VERSION ""

NS_ :

BS_:

BU_: HCU BMS MCU

BO_ 534 MCU_STATUS_4: 8 MCU
 SG_ LiveCounter4 : 63|4@0+ (1,0) [0|0] "" Vector__XXX
 SG_ MotorRotationCount : 55|8@0+ (1,0) [0|0] "" Vector__XXX
 SG_ DCVoltage : 39|16@0+ (1,0) [0|65535] "" Vector__XXX
 SG_ IPMError : 8|1@0+ (1,0) [0|0] "" Vector__XXX
 SG_ UnderVoltageError : 9|1@0+ (1,0) [0|0] "" Vector__XXX
 SG_ Under12vVoltageError : 10|1@0+ (1,0) [0|0] "" Vector__XXX
 SG_ InverterOverTemperatureWarning : 11|1@0+ (1,0) [0|0] "" Vector__XXX
 SG_ WindingOverTemperatureWarning : 12|1@0+ (1,0) [0|0] "" Vector__XXX
 SG_ UnderVoltageWarning : 13|1@0+ (1,0) [0|0] "" Vector__XXX
 SG_ DC_Current : 23|16@0+ (1,-1000) [-1000|1000] "A" Vector__XXX
 SG_ OverVoltageWarning : 14|1@0+ (1,0) [0|0] "" Vector__XXX
 SG_ CANCommunicationError : 7|1@0+ (1,0) [0|0] "" Vector__XXX
 SG_ WindingTemperatureSensorError : 6|1@0+ (1,0) [0|0] "" Vector__XXX
 SG_ ResolverError : 5|1@0+ (1,0) [0|0] "" Vector__XXX
 SG_ InverterOverTemperatureError : 4|1@0+ (1,0) [0|0] "" Vector__XXX
 SG_ WindingOverTemperatureError : 3|1@0+ (1,0) [0|0] "" Vector__XXX
 SG_ OverSpeedError : 2|1@0+ (1,0) [0|0] "" Vector__XXX
 SG_ OverCurrentError : 1|1@0+ (1,0) [0|0] "" Vector__XXX
 SG_ OverVoltageError : 0|1@0+ (1,0) [0|0] "" Vector__XXX

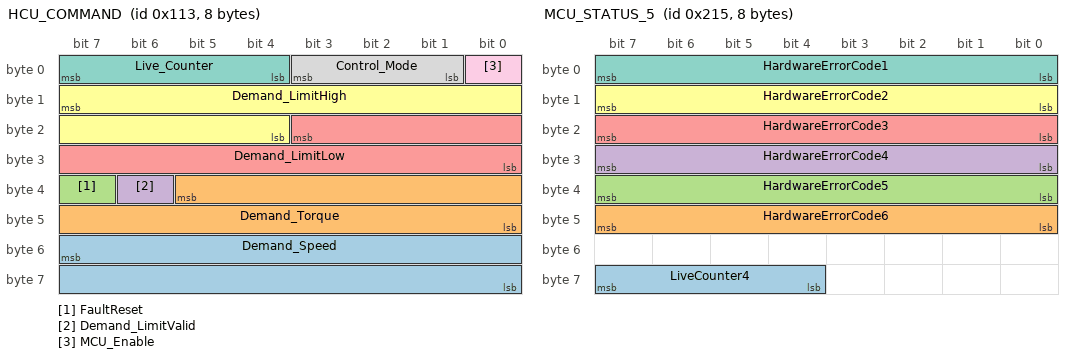
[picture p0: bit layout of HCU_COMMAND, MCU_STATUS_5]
BO_ 275 HCU_COMMAND: 8 HCU
 SG_ Demand_Speed : 55|16@0+ (1,-15000) [0|0] "" Vector__XXX
 SG_ Demand_Torque : 37|14@0+ (1,-5000) [0|0] "" Vector__XXX
 SG_ FaultReset : 39|1@0+ (1,0) [0|0] "" Vector__XXX
 SG_ Demand_LimitValid : 38|1@0+ (1,0) [0|0] "" Vector__XXX
 SG_ Demand_LimitLow : 19|12@0+ (4,0) [0|0] "" Vector__XXX
 SG_ Demand_LimitHigh : 15|12@0+ (4,0) [0|0] "" Vector__XXX
 SG_ Live_Counter : 7|4@0+ (1,0) [0|0] "" Vector__XXX
 SG_ Control_Mode : 3|3@0+ (1,0) [0|0] "" Vector__XXX
 SG_ MCU_Enable : 0|1@0+ (1,0) [0|0] "" Vector__XXX

BO_ 533 MCU_STATUS_5: 8 MCU
 SG_ LiveCounter4 : 63|4@0+ (1,0) [0|15] "" Vector__XXX
 SG_ HardwareErrorCode6 : 47|8@0+ (1,0) [0|0] "" Vector__XXX
 SG_ HardwareErrorCode5 : 39|8@0+ (1,0) [0|0] "" Vector__XXX
 SG_ HardwareErrorCode4 : 31|8@0+ (1,0) [0|0] "" Vector__XXX
 SG_ HardwareErrorCode3 : 23|8@0+ (1,0) [0|0] "" Vector__XXX
 SG_ HardwareErrorCode2 : 15|8@0+ (1,0) [0|0] "" Vector__XXX
 SG_ HardwareErrorCode1 : 7|8@0+ (1,0) [0|0] "" Vector__XXX

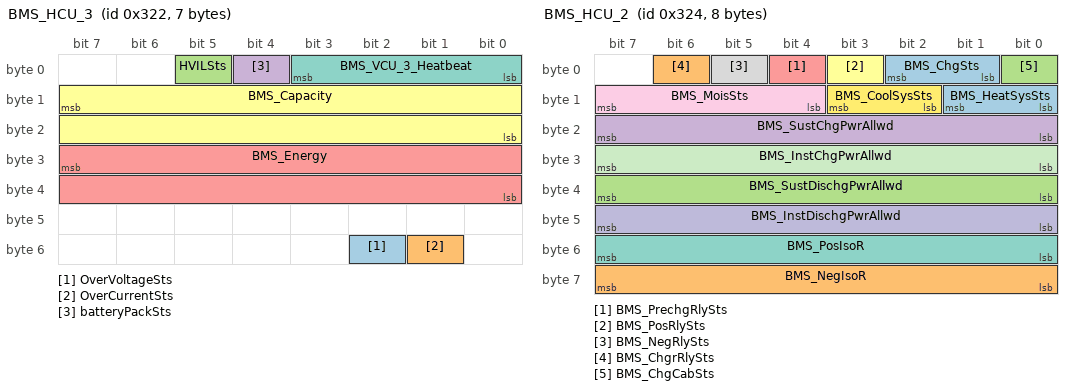
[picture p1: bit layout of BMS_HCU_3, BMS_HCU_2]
BO_ 802 BMS_HCU_3: 7 BMS
 SG_ OverVoltageSts : 50|1@0+ (1,0) [0|0] "" Vector__XXX
 SG_ OverCurrentSts : 49|1@0+ (1,0) [0|0] "" Vector__XXX
 SG_ HVILSts : 5|1@0+ (1,0) [0|0] "" Vector__XXX
 SG_ batteryPackSts : 4|1@0+ (1,0) [0|0] "" Vector__XXX
 SG_ BMS_Energy : 31|16@0+ (0.01,0) [0|200] "" Vector__XXX
 SG_ BMS_Capacity : 15|16@0+ (0.01,0) [0|655.35] "" Vector__XXX
 SG_ BMS_VCU_3_Heatbeat : 3|4@0+ (1,0) [0|15] "" Vector__XXX

BO_ 804 BMS_HCU_2: 8 BMS
 SG_ BMS_HeatSysSts : 9|2@0+ (1,0) [0|0] "" Vector__XXX
 SG_ BMS_NegIsoR : 63|8@0+ (10,0) [0|2550] "k¦¸" Vector__XXX
 SG_ BMS_SustDischgPwrAllwd : 39|8@0+ (1,0) [0|200] "kW" Vector__XXX
 SG_ BMS_SustChgPwrAllwd : 23|8@0+ (1,-200) [-200|0] "kW" Vector__XXX
 SG_ BMS_PrechgRlySts : 4|1@0+ (1,0) [0|3] "" Vector__XXX
 SG_ BMS_PosRlySts : 3|1@0+ (1,0) [0|3] "" Vector__XXX
 SG_ BMS_PosIsoR : 55|8@0+ (10,0) [0|2550] "k¦¸" Vector__XXX
 SG_ BMS_NegRlySts : 5|1@0+ (1,0) [0|3] "" Vector__XXX
 SG_ BMS_MoisSts : 15|4@0+ (10,0) [0|15] "%" Vector__XXX
 SG_ BMS_InstDischgPwrAllwd : 47|8@0+ (1,0) [0|200] "kW" Vector__XXX
 SG_ BMS_InstChgPwrAllwd : 31|8@0+ (1,-200) [-200|0] "kW" Vector__XXX
 SG_ BMS_CoolSysSts : 11|2@0+ (1,0) [0|1] "" Vector__XXX
 SG_ BMS_ChgSts : 2|2@0+ (1,0) [0|3] "" Vector__XXX
 SG_ BMS_ChgrRlySts : 6|1@0+ (1,0) [0|1] "" Vector__XXX
 SG_ BMS_ChgCabSts : 0|1@0+ (1,0) [0|1] "" Vector__XXX

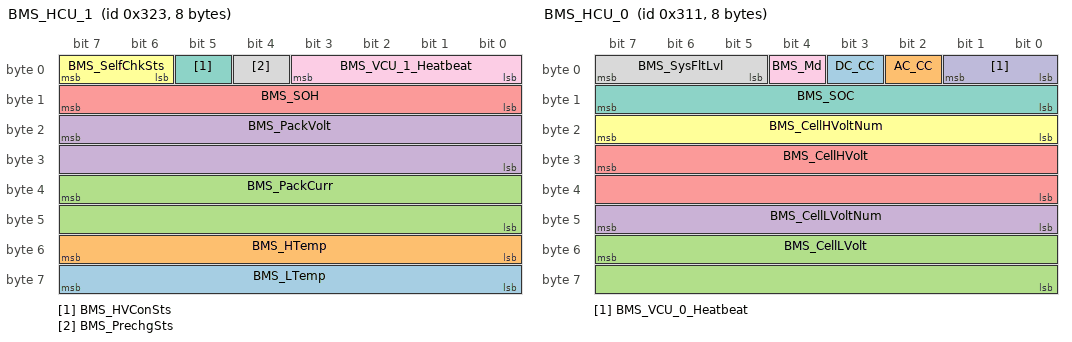
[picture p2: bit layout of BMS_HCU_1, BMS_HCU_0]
BO_ 803 BMS_HCU_1: 8 BMS
 SG_ BMS_LTemp : 63|8@0+ (1,-40) [-40|200] "¡æ" Vector__XXX
 SG_ BMS_HTemp : 55|8@0+ (1,-40) [-40|200] "¡æ" Vector__XXX
 SG_ BMS_PackCurr : 39|16@0+ (1,-1000) [-1000|1000] "A" Vector__XXX
 SG_ BMS_PackVolt : 23|16@0+ (1,0) [0|800] "V" Vector__XXX
 SG_ BMS_SOH : 15|8@0+ (1,0) [0|100] "%" Vector__XXX
 SG_ BMS_SelfChkSts : 7|2@0+ (1,0) [0|3] "" Vector__XXX
 SG_ BMS_HVConSts : 5|1@0+ (1,0) [0|1] "" Vector__XXX
 SG_ BMS_PrechgSts : 4|1@0+ (1,0) [0|1] "" Vector__XXX
 SG_ BMS_VCU_1_Heatbeat : 3|4@0+ (1,0) [0|15] "" Vector__XXX

BO_ 785 BMS_HCU_0: 8 BMS
 SG_ DC_CC : 3|1@0+ (1,0) [0|0] "" Vector__XXX
 SG_ AC_CC : 2|1@0+ (1,0) [0|0] "" Vector__XXX
 SG_ BMS_CellLVolt : 55|16@0+ (0.00390625,0) [0|255.99609375] "V" Vector__XXX
 SG_ BMS_CellLVoltNum : 47|8@0+ (1,0) [0|255] "" Vector__XXX
 SG_ BMS_CellHVolt : 31|16@0+ (0.00390625,0) [0|0] "V" Vector__XXX
 SG_ BMS_CellHVoltNum : 23|8@0+ (1,0) [0|255] "" Vector__XXX
 SG_ BMS_SOC : 15|8@0+ (0.5,0) [0|100] "%" Vector__XXX
 SG_ BMS_SysFltLvl : 7|3@0+ (1,0) [0|4] "" Vector__XXX
 SG_ BMS_Md : 4|1@0+ (1,0) [0|1] "" Vector__XXX
 SG_ BMS_VCU_0_Heatbeat : 1|2@0+ (1,0) [0|3] "" Vector__XXX

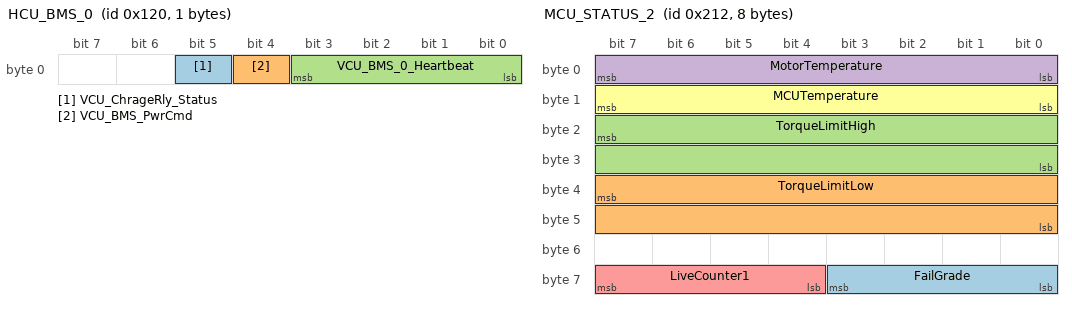
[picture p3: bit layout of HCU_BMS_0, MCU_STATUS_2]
BO_ 288 HCU_BMS_0: 1 HCU
 SG_ VCU_ChrageRly_Status : 5|1@0+ (1,0) [0|0] ""  BMS
 SG_ VCU_BMS_PwrCmd : 4|1@0+ (1,0) [0|1] ""  BMS
 SG_ VCU_BMS_0_Heartbeat : 3|4@0+ (1,0) [0|15] ""  BMS

BO_ 530 MCU_STATUS_2: 8 MCU
 SG_ FailGrade : 59|4@0+ (1,0) [0|0] "" Vector__XXX
 SG_ TorqueLimitLow : 39|16@0+ (1,-5000) [-5000|0] "" Vector__XXX
 SG_ TorqueLimitHigh : 23|16@0+ (1,0) [0|5000] "Nm" Vector__XXX
 SG_ MotorTemperature : 7|8@0+ (1,-40) [-40|215] "¡æ" Vector__XXX
 SG_ LiveCounter1 : 63|4@0+ (1,0) [0|15] "" Vector__XXX
 SG_ MCUTemperature : 15|8@0+ (1,-40) [-40|215] "¡æ" Vector__XXX

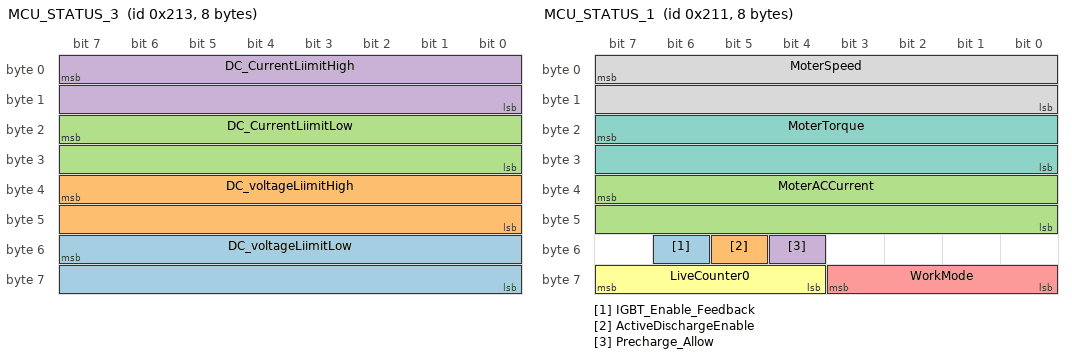
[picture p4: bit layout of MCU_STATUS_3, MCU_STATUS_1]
BO_ 531 MCU_STATUS_3: 8 MCU
 SG_ DC_voltageLiimitLow : 55|16@0+ (0.1,-750) [0|0] "" Vector__XXX
 SG_ DC_voltageLiimitHigh : 39|16@0+ (0.1,0) [0|0] "" Vector__XXX
 SG_ DC_CurrentLiimitLow : 23|16@0+ (0.1,-400) [0|0] "" Vector__XXX
 SG_ DC_CurrentLiimitHigh : 7|16@0+ (0.1,0) [0|0] "" Vector__XXX

BO_ 529 MCU_STATUS_1: 8 MCU
 SG_ IGBT_Enable_Feedback : 54|1@0+ (1,0) [0|0] "" Vector__XXX
 SG_ ActiveDischargeEnable : 53|1@0+ (1,0) [0|0] "" Vector__XXX
 SG_ MoterACCurrent : 39|16@0+ (0.1,0) [0|1000] "" Vector__XXX
 SG_ Precharge_Allow : 52|1@0+ (1,0) [0|1] "" Vector__XXX
 SG_ WorkMode : 59|4@0+ (1,0) [0|8] "" Vector__XXX
 SG_ LiveCounter0 : 63|4@0+ (1,0) [0|15] "" Vector__XXX
 SG_ MoterTorque : 23|16@0+ (1,-5000) [-5000|5000] "Nm" Vector__XXX
 SG_ MoterSpeed : 7|16@0+ (1,-15000) [-15000|15000] "rpm" Vector__XXX

BA_DEF_ SG_  "GenSigSendType" ENUM  "Cyclic","OnWrite","OnWriteWithRepetition","OnChange","OnChangeWithRepetition","IfActive","IfActiveWithRepetition";
BA_DEF_ SG_  "GenSigEnvVarType" ENUM  "int","float","undef";
BA_DEF_ BO_  "GenMsgILSupport" ENUM  "No","Yes";
BA_DEF_ BO_  "GenMsgCycleTimeFast" INT 2 100000;
BA_DEF_ BO_  "GenMsgSendType" ENUM  "Cyclic","not_used","not_used","not_used","not_used","Cyclic","not_used","IfActive";
BA_DEF_ BO_  "GenMsgCycleTime" INT 2 50000;
BA_DEF_ BO_  "GenMsgDelayTime" INT 1 1000;
BA_DEF_ BU_  "TpAddressingMode" INT 0 3;
BA_DEF_ BU_  "ILUsed" ENUM  "Yes","No";
BA_DEF_ BU_  "TpTxIdentifier" HEX 0 536870911;
BA_DEF_ BU_  "TpRxIdentifier" HEX 0 536870911;
BA_DEF_ BU_  "TpRxMask" HEX 0 65535;
BA_DEF_ BU_  "TpCanBus" INT 1 2;
BA_DEF_ BU_  "TpUseFC" INT 0 1;
BA_DEF_ BU_  "TpNodeBaseAddress" HEX 0 33554431;
BA_DEF_  "DBName" STRING ;
BA_DEF_  "GenEnvVarEndingDsp" STRING ;
BA_DEF_  "GenEnvVarEndingSnd" STRING ;
BA_DEF_  "GenEnvVarPrefix" STRING ;
BA_DEF_  "NmBaseAddress" HEX 1024 1055;
BA_DEF_  "GenNWMApCanOff" STRING ;
BA_DEF_  "GenNWMApCanOn" STRING ;
BA_DEF_  "GenNWMApCanSleep" STRING ;
BA_DEF_  "GenNWMGotoMode_Awake" STRING ;
BA_DEF_  "GenNWMGotoMode_BusSleep" STRING ;
BA_DEF_  "GenNWMTalkNM" STRING ;
BA_DEF_DEF_  "GenSigSendType" "Cyclic";
BA_DEF_DEF_  "GenSigEnvVarType" "undef";
BA_DEF_DEF_  "GenMsgILSupport" "Yes";
BA_DEF_DEF_  "GenMsgCycleTimeFast" 100;
BA_DEF_DEF_  "GenMsgSendType" "not_used";
BA_DEF_DEF_  "GenMsgCycleTime" 2;
BA_DEF_DEF_  "GenMsgDelayTime" 1;
BA_DEF_DEF_  "TpAddressingMode" 1;
BA_DEF_DEF_  "ILUsed" "Yes";
BA_DEF_DEF_  "TpTxIdentifier" 1;
BA_DEF_DEF_  "TpRxIdentifier" 1;
BA_DEF_DEF_  "TpRxMask" 255;
BA_DEF_DEF_  "TpCanBus" 1;
BA_DEF_DEF_  "TpUseFC" 1;
BA_DEF_DEF_  "TpNodeBaseAddress" 1536;
BA_DEF_DEF_  "DBName" "";
BA_DEF_DEF_  "GenEnvVarEndingDsp" "Dsp_";
BA_DEF_DEF_  "GenEnvVarEndingSnd" "_";
BA_DEF_DEF_  "GenEnvVarPrefix" "Env";
BA_DEF_DEF_  "NmBaseAddress" 1024;
BA_DEF_DEF_  "GenNWMApCanOff" "apCanOff()";
BA_DEF_DEF_  "GenNWMApCanOn" "apCanOn()";
BA_DEF_DEF_  "GenNWMApCanSleep" "apCanSleep()";
BA_DEF_DEF_  "GenNWMGotoMode_Awake" "GotoMode_Awake()";
BA_DEF_DEF_  "GenNWMGotoMode_BusSleep" "GotoMode_BusSleep()";
BA_DEF_DEF_  "GenNWMTalkNM" "TalkNM()";
BA_ "DBName" "EV_Demo";
BA_ "GenMsgSendType" BO_ 534 0;
BA_ "GenMsgCycleTime" BO_ 534 100;
BA_ "GenMsgSendType" BO_ 275 0;
BA_ "GenMsgCycleTime" BO_ 275 10;
BA_ "GenMsgSendType" BO_ 533 0;
BA_ "GenMsgCycleTime" BO_ 533 200;
BA_ "GenMsgSendType" BO_ 802 0;
BA_ "GenMsgCycleTime" BO_ 802 100;
BA_ "GenMsgSendType" BO_ 804 0;
BA_ "GenMsgCycleTime" BO_ 804 50;
BA_ "GenMsgSendType" BO_ 803 0;
BA_ "GenMsgCycleTime" BO_ 803 20;
BA_ "GenMsgSendType" BO_ 785 0;
BA_ "GenMsgCycleTime" BO_ 785 10;
BA_ "GenMsgSendType" BO_ 288 0;
BA_ "GenMsgCycleTime" BO_ 288 20;
BA_ "GenMsgSendType" BO_ 530 0;
BA_ "GenMsgCycleTime" BO_ 530 20;
BA_ "GenMsgSendType" BO_ 531 0;
BA_ "GenMsgCycleTime" BO_ 531 50;
BA_ "GenMsgSendType" BO_ 529 0;
BA_ "GenMsgCycleTime" BO_ 529 10;
